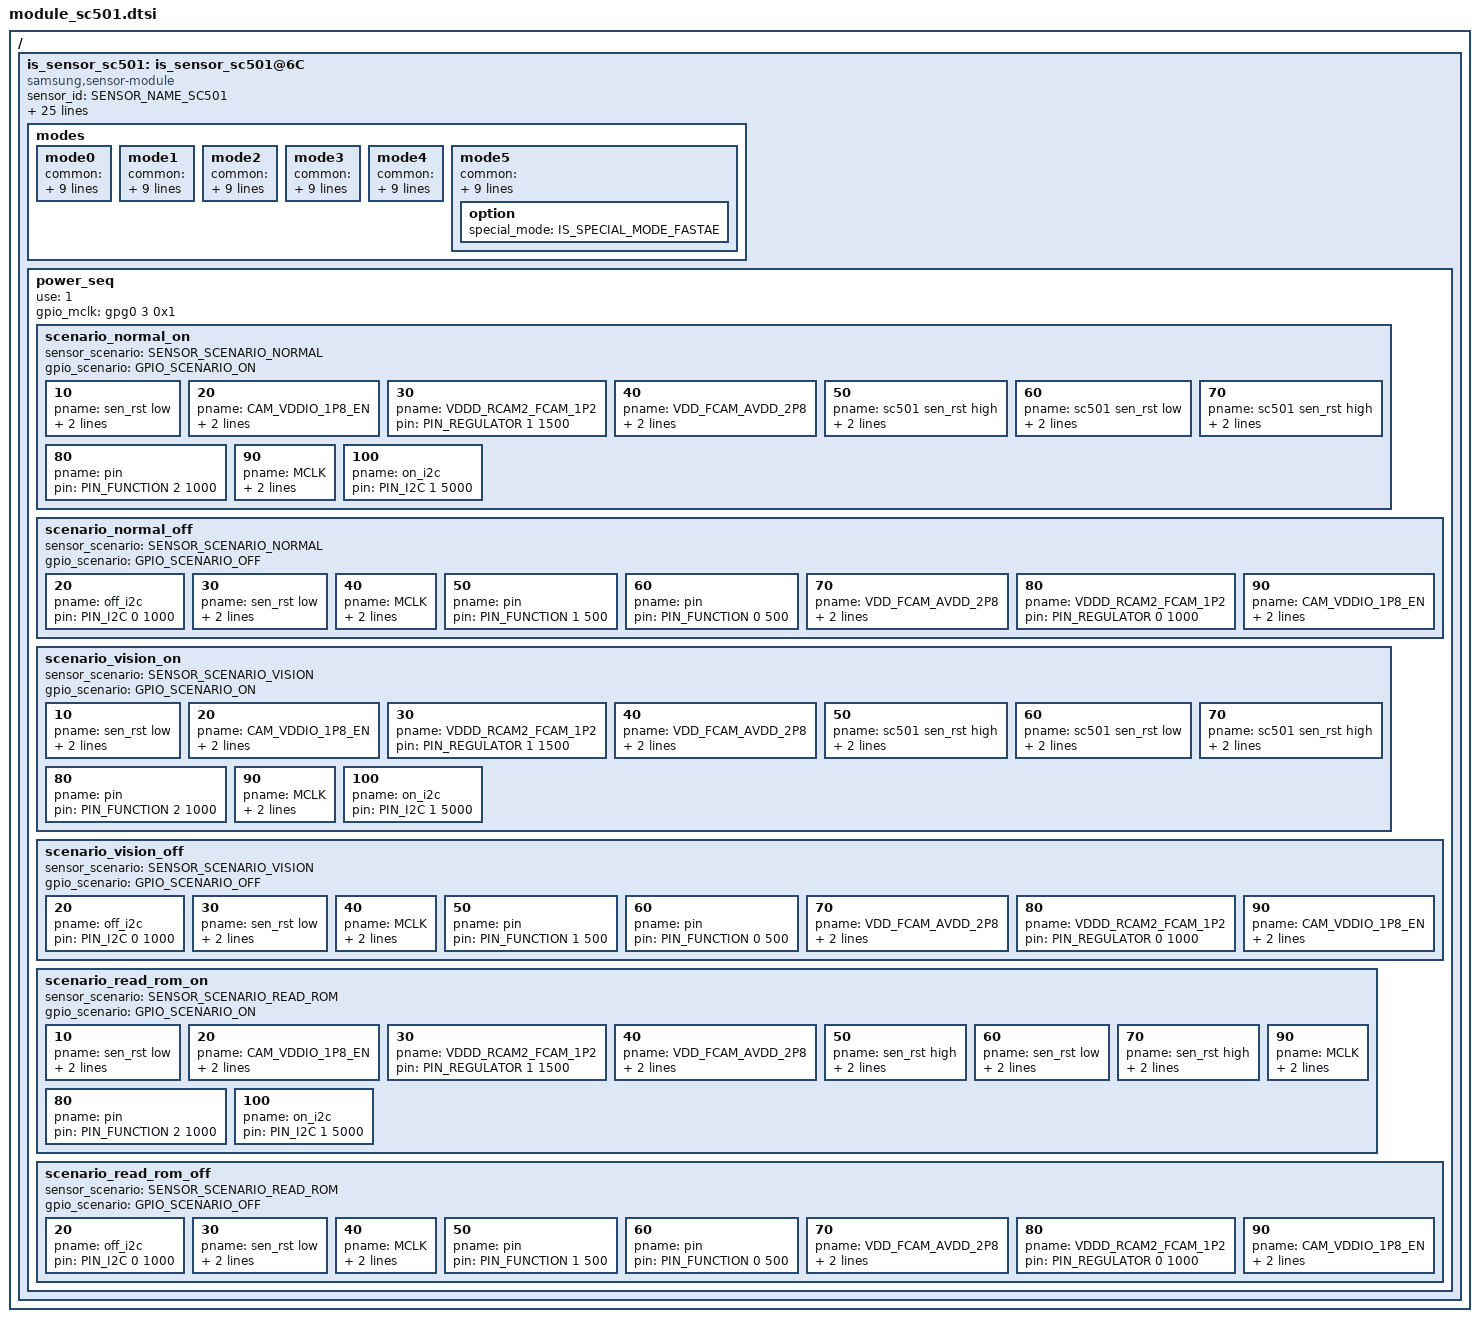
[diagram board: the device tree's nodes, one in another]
/*
 * SAMSUNG EXYNOSxxxx board camera device tree source
 *
 * Copyright (c) 2021 Samsung Electronics Co., Ltd.
 *		http://www.samsung.com
 *
 * This program is free software; you can redistribute it and/or modify
 * it under the terms of the GNU General Public License version 2 as
 * published by the Free Software Foundation.
 */

#include <dt-bindings/camera/exynos_is_dt.h>

/ {
	fragment@camera {
		target-path = "/";
		__overlay__ {
			is_sensor_sc501: is_sensor_sc501@6C {
				compatible = "samsung,sensor-module";

				/* common */
				sensor_id = <SENSOR_NAME_SC501>;
				active_width = <2592>;
				active_height = <1944>;
				margin_left = <0>;
				margin_right = <0>;
				margin_top = <0>;
				margin_bottom = <0>;
				max_framerate = <60>;
				bitwidth = <10>;
				use_retention_mode = <SENSOR_RETENTION_INACTIVE>;
				sensor_maker = "SMARTSENS";
				sensor_name = "SC501";
				setfile_name = "setfile_sc501.bin";
				pinning_setfile;
				preload_setfile;

				status = "okay";

				/* board */
				pinctrl-names = "pin0", "pin1", "pin2", "release";
				pinctrl-0 = <>;
				pinctrl-1 = <&sensor_mclk1_out>;
				pinctrl-2 = <&sensor_mclk1_fn>;
				pinctrl-3 = <>;

				position = <4>; /* Rear:0. Front:1, Tele:2 */
				id = <4>; /* is_sensor id */
				mclk_ch = <1>;
				sensor_i2c_ch = <3>; /* SENSOR_CONTROL_I2C3 */

				/* vendor */
				rom_type = <3>; /* ROM_TYPE_OTPROM */
				rom_id = <4>;
				rom_cal_index = <0>;
				/* sensor modes */
				modes {
						/* common = <width, height, fps, settle, mode, lane, speed, interleave, lrte, pd_mode> */
						/* vcX = <map, hwformat, width, height, hwformat, type, width, height> */

					/* 0 : 2576x1932@30fps 4:3 */
					mode0 {
						common = <2576 1932 30 0 0 CSI_DATA_LANES_2 897 CSI_MODE_VC_ONLY LRTE_DISABLE PD_NONE EX_NONE>;
						vc0 = </* in */ 0 HW_FORMAT_RAW10 2576 1932	/* out */ HW_FORMAT_RAW10 VC_NOTHING 0 0>;
						vc1 = </* in */ 1 HW_FORMAT_UNKNOWN 0 0		/* out */ HW_FORMAT_UNKNOWN VC_NOTHING 0 0>;
						vc2 = </* in */ 2 HW_FORMAT_UNKNOWN 0 0		/* out */ HW_FORMAT_UNKNOWN VC_NOTHING 0 0>;
						vc3 = </* in */ 3 HW_FORMAT_UNKNOWN 0 0		/* out */ HW_FORMAT_UNKNOWN VC_NOTHING 0 0>;
					};

					/* 1 : 2560x1440@30fps 16:9 */
					mode1 {
						common = <2560 1440 30 0 1 CSI_DATA_LANES_2 897 CSI_MODE_VC_ONLY LRTE_DISABLE PD_NONE EX_NONE>;
						vc0 = </* in */ 0 HW_FORMAT_RAW10 2560 1440	/* out */ HW_FORMAT_RAW10 VC_NOTHING 0 0>;
						vc1 = </* in */ 1 HW_FORMAT_UNKNOWN 0 0		/* out */ HW_FORMAT_UNKNOWN VC_NOTHING 0 0>;
						vc2 = </* in */ 2 HW_FORMAT_UNKNOWN 0 0		/* out */ HW_FORMAT_UNKNOWN VC_NOTHING 0 0>;
						vc3 = </* in */ 3 HW_FORMAT_UNKNOWN 0 0		/* out */ HW_FORMAT_UNKNOWN VC_NOTHING 0 0>;
					};

					/* 2 : 2416x1660@30fps */
					mode2 {
						common = <2416 1660 30 0 2 CSI_DATA_LANES_2 897 CSI_MODE_VC_ONLY LRTE_DISABLE PD_NONE EX_NONE>;
						vc0 = </* in */ 0 HW_FORMAT_RAW10 2416 1660	/* out */ HW_FORMAT_RAW10 VC_NOTHING 0 0>;
						vc1 = </* in */ 1 HW_FORMAT_UNKNOWN 0 0		/* out */ HW_FORMAT_UNKNOWN VC_NOTHING 0 0>;
						vc2 = </* in */ 2 HW_FORMAT_UNKNOWN 0 0		/* out */ HW_FORMAT_UNKNOWN VC_NOTHING 0 0>;
						vc3 = </* in */ 3 HW_FORMAT_UNKNOWN 0 0		/* out */ HW_FORMAT_UNKNOWN VC_NOTHING 0 0>;
					};

					/* 3 : 1280x960@30fps 4:3 */
					mode3 {
						common = <1280 960 30 0 3 CSI_DATA_LANES_2 448 CSI_MODE_VC_ONLY LRTE_DISABLE PD_NONE EX_NONE>;
						vc0 = </* in */ 0 HW_FORMAT_RAW10 1280 960	/* out */ HW_FORMAT_RAW10 VC_NOTHING 0 0>;
						vc1 = </* in */ 1 HW_FORMAT_UNKNOWN 0 0		/* out */ HW_FORMAT_UNKNOWN VC_NOTHING 0 0>;
						vc2 = </* in */ 2 HW_FORMAT_UNKNOWN 0 0		/* out */ HW_FORMAT_UNKNOWN VC_NOTHING 0 0>;
						vc3 = </* in */ 3 HW_FORMAT_UNKNOWN 0 0		/* out */ HW_FORMAT_UNKNOWN VC_NOTHING 0 0>;
					};

					/* 4 : 1280x720@30fps 16:9 */
					mode4 {
						common = <1280 720 30 0 4 CSI_DATA_LANES_2 448 CSI_MODE_VC_ONLY LRTE_DISABLE PD_NONE EX_NONE>;
						vc0 = </* in */ 0 HW_FORMAT_RAW10 1280 720	/* out */ HW_FORMAT_RAW10 VC_NOTHING 0 0>;
						vc1 = </* in */ 1 HW_FORMAT_UNKNOWN 0 0		/* out */ HW_FORMAT_UNKNOWN VC_NOTHING 0 0>;
						vc2 = </* in */ 2 HW_FORMAT_UNKNOWN 0 0		/* out */ HW_FORMAT_UNKNOWN VC_NOTHING 0 0>;
						vc3 = </* in */ 3 HW_FORMAT_UNKNOWN 0 0		/* out */ HW_FORMAT_UNKNOWN VC_NOTHING 0 0>;
					};

					/* 5 : 1280x960@60fps 4:3 */
					mode5 {
						common = <1280 960 60 0 5 CSI_DATA_LANES_2 448 CSI_MODE_VC_ONLY LRTE_DISABLE PD_NONE EX_NONE>;
						vc0 = </* in */ 0 HW_FORMAT_RAW10 1280 960	/* out */ HW_FORMAT_RAW10 VC_NOTHING 0 0>;
						vc1 = </* in */ 1 HW_FORMAT_UNKNOWN 0 0		/* out */ HW_FORMAT_UNKNOWN VC_NOTHING 0 0>;
						vc2 = </* in */ 2 HW_FORMAT_UNKNOWN 0 0		/* out */ HW_FORMAT_UNKNOWN VC_NOTHING 0 0>;
						vc3 = </* in */ 3 HW_FORMAT_UNKNOWN 0 0		/* out */ HW_FORMAT_UNKNOWN VC_NOTHING 0 0>;
						option { special_mode = <IS_SPECIAL_MODE_FASTAE>; };
					};
				};

				power_seq {
					use = <1>;
					gpio_mclk = <&gpg0 3 0x1>;
					scenario_normal_on {
						sensor_scenario = <SENSOR_SCENARIO_NORMAL>;
						gpio_scenario = <GPIO_SCENARIO_ON>;

						/* A start node number should be over the 10 for reserved number 0~9. */
						/* pname = "name"; pin = <act value dealy voltage>; gpio = <gpx# # 0x1>; */

						10 { pname = "sen_rst low"; pin = <PIN_OUTPUT 0 500>; gpio = <&gpm8 0 0x1>; };
						20 { pname = "CAM_VDDIO_1P8_EN"; pin = <PIN_OUTPUT 1 1500>; gpio = <&gpp0 7 0x1>;  };
						30 { pname = "VDDD_RCAM2_FCAM_1P2"; pin = <PIN_REGULATOR 1 1500>;   };
						40 { pname = "VDD_FCAM_AVDD_2P8"; pin = <PIN_OUTPUT 1 1000>; gpio = <&gpp1 2 0x1>;  };
						50 { pname = "sc501 sen_rst high"; pin = <PIN_OUTPUT 1 1500>; gpio = <&gpm8 0 0x1>; };
						60 { pname = "sc501 sen_rst low"; pin = <PIN_OUTPUT 0 1500>; gpio = <&gpm8 0 0x1>; };
						70 { pname = "sc501 sen_rst high"; pin = <PIN_OUTPUT 1 2000>; gpio = <&gpm8 0 0x1>; };
						80 { pname = "pin"; pin = <PIN_FUNCTION 2 1000>; };
						90 { pname = "MCLK"; pin = <PIN_MCLK 1 0>; gpio = <&gpg0 3 0x1>; };
						100 { pname = "on_i2c"; pin = <PIN_I2C 1 5000>; };
					};

					scenario_normal_off {
						sensor_scenario = <SENSOR_SCENARIO_NORMAL>;
						gpio_scenario = <GPIO_SCENARIO_OFF>;

						/* A start node number should be over the 10 for reserved number 0~9. */
						/* pname = "name"; pin = <act value dealy voltage>; gpio = <gpx# # 0x1>; */
						20 { pname = "off_i2c"; pin = <PIN_I2C 0 1000>; };
						30 { pname = "sen_rst low"; pin = <PIN_OUTPUT 0 500>; gpio = <&gpm8 0 0x1>; };
						40 { pname = "MCLK"; pin = <PIN_MCLK 0 1000>; gpio = <&gpg0 3 0x1>; };
						50 { pname = "pin"; pin = <PIN_FUNCTION 1 500>; };
						60 { pname = "pin"; pin = <PIN_FUNCTION 0 500>; };
						70 { pname = "VDD_FCAM_AVDD_2P8"; pin = <PIN_OUTPUT 0 500>; gpio = <&gpp1 2 0x1>;  };
						80 { pname = "VDDD_RCAM2_FCAM_1P2"; pin = <PIN_REGULATOR 0 1000>;   };
						90 { pname = "CAM_VDDIO_1P8_EN"; pin = <PIN_OUTPUT 0 500>; gpio = <&gpp0 7 0x1>;  };
					};

					scenario_vision_on {
						sensor_scenario = <SENSOR_SCENARIO_VISION>;
						gpio_scenario = <GPIO_SCENARIO_ON>;

						/* A start node number should be over the 10 for reserved number 0~9. */
						/* pname = "name"; pin = <act value dealy voltage>; gpio = <gpx# # 0x1>; */

						10 { pname = "sen_rst low"; pin = <PIN_OUTPUT 0 500>; gpio = <&gpm8 0 0x1>; };
						20 { pname = "CAM_VDDIO_1P8_EN"; pin = <PIN_OUTPUT 1 1500>; gpio = <&gpp0 7 0x1>;  };
						30 { pname = "VDDD_RCAM2_FCAM_1P2"; pin = <PIN_REGULATOR 1 1500>;   };
						40 { pname = "VDD_FCAM_AVDD_2P8"; pin = <PIN_OUTPUT 1 1000>; gpio = <&gpp1 2 0x1>;  };
						50 { pname = "sc501 sen_rst high"; pin = <PIN_OUTPUT 1 1500>; gpio = <&gpm8 0 0x1>; };
						60 { pname = "sc501 sen_rst low"; pin = <PIN_OUTPUT 0 1500>; gpio = <&gpm8 0 0x1>; };
						70 { pname = "sc501 sen_rst high"; pin = <PIN_OUTPUT 1 2000>; gpio = <&gpm8 0 0x1>; };
						80 { pname = "pin"; pin = <PIN_FUNCTION 2 1000>; };
						90 { pname = "MCLK"; pin = <PIN_MCLK 1 0>; gpio = <&gpg0 3 0x1>; };
						100 { pname = "on_i2c"; pin = <PIN_I2C 1 5000>; };
					};

					scenario_vision_off {
						sensor_scenario = <SENSOR_SCENARIO_VISION>;
						gpio_scenario = <GPIO_SCENARIO_OFF>;

						/* A start node number should be over the 10 for reserved number 0~9. */
						/* pname = "name"; pin = <act value dealy voltage>; gpio = <gpx# # 0x1>; */
						20 { pname = "off_i2c"; pin = <PIN_I2C 0 1000>; };
						30 { pname = "sen_rst low"; pin = <PIN_OUTPUT 0 500>; gpio = <&gpm8 0 0x1>; };
						40 { pname = "MCLK"; pin = <PIN_MCLK 0 1000>; gpio = <&gpg0 3 0x1>; };
						50 { pname = "pin"; pin = <PIN_FUNCTION 1 500>; };
						60 { pname = "pin"; pin = <PIN_FUNCTION 0 500>; };
						70 { pname = "VDD_FCAM_AVDD_2P8"; pin = <PIN_OUTPUT 0 500>; gpio = <&gpp1 2 0x1>;  };
						80 { pname = "VDDD_RCAM2_FCAM_1P2"; pin = <PIN_REGULATOR 0 1000>;   };
						90 { pname = "CAM_VDDIO_1P8_EN"; pin = <PIN_OUTPUT 0 500>; gpio = <&gpp0 7 0x1>;  };
					};

					scenario_read_rom_on {
						sensor_scenario = <SENSOR_SCENARIO_READ_ROM>;
						gpio_scenario = <GPIO_SCENARIO_ON>;

						/* A start node number should be over the 10 for reserved number 0~9. */
						/* pname = "name"; pin = <act value dealy voltage>; gpio = <gpx# # 0x1>; */

						10 { pname = "sen_rst low"; pin = <PIN_OUTPUT 0 500>; gpio = <&gpm8 0 0x1>; };
						20 { pname = "CAM_VDDIO_1P8_EN"; pin = <PIN_OUTPUT 1 1500>; gpio = <&gpp0 7 0x1>;  };
						30 { pname = "VDDD_RCAM2_FCAM_1P2"; pin = <PIN_REGULATOR 1 1500>;   };
						40 { pname = "VDD_FCAM_AVDD_2P8"; pin = <PIN_OUTPUT 1 1000>; gpio = <&gpp1 2 0x1>;  };
						50 { pname = "sen_rst high"; pin = <PIN_OUTPUT 1 1500>; gpio = <&gpm8 0 0x1>; };
						60 { pname = "sen_rst low"; pin = <PIN_OUTPUT 0 1500>; gpio = <&gpm8 0 0x1>; };
						70 { pname = "sen_rst high"; pin = <PIN_OUTPUT 1 2000>; gpio = <&gpm8 0 0x1>; };
						80 { pname = "pin"; pin = <PIN_FUNCTION 2 1000>; };
						90 { pname = "MCLK"; pin = <PIN_MCLK 1 0>; gpio = <&gpg0 3 0x1>; };
						100 { pname = "on_i2c"; pin = <PIN_I2C 1 5000>; };
					};

					scenario_read_rom_off {
						sensor_scenario = <SENSOR_SCENARIO_READ_ROM>;
						gpio_scenario = <GPIO_SCENARIO_OFF>;

						/* A start node number should be over the 10 for reserved number 0~9. */
						/* pname = "name"; pin = <act value dealy voltage>; gpio = <gpx# # 0x1>; */
						20 { pname = "off_i2c"; pin = <PIN_I2C 0 1000>; };
						30 { pname = "sen_rst low"; pin = <PIN_OUTPUT 0 500>; gpio = <&gpm8 0 0x1>; };
						40 { pname = "MCLK"; pin = <PIN_MCLK 0 1000>; gpio = <&gpg0 3 0x1>; };
						50 { pname = "pin"; pin = <PIN_FUNCTION 1 500>; };
						60 { pname = "pin"; pin = <PIN_FUNCTION 0 500>; };
						70 { pname = "VDD_FCAM_AVDD_2P8"; pin = <PIN_OUTPUT 0 500>; gpio = <&gpp1 2 0x1>;  };
						80 { pname = "VDDD_RCAM2_FCAM_1P2"; pin = <PIN_REGULATOR 0 1000>;   };
						90 { pname = "CAM_VDDIO_1P8_EN"; pin = <PIN_OUTPUT 0 500>; gpio = <&gpp0 7 0x1>;  };
					};
				};
			};
		}; /* end of __overlay__ */
	}; /* end of fragment */
}; /* end of root */
